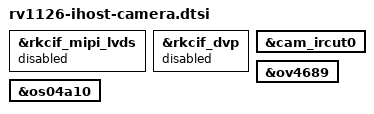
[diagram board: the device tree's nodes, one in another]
&rkcif_mipi_lvds {
    status = "disabled";
};

&rkcif_dvp {
    status = "disabled";
};

&cam_ircut0 {
    status = "okay";
};

&ov4689 {
    /delete-property/ reset-gpios;
};

&os04a10 {
    /delete-property/ reset-gpios;
};
